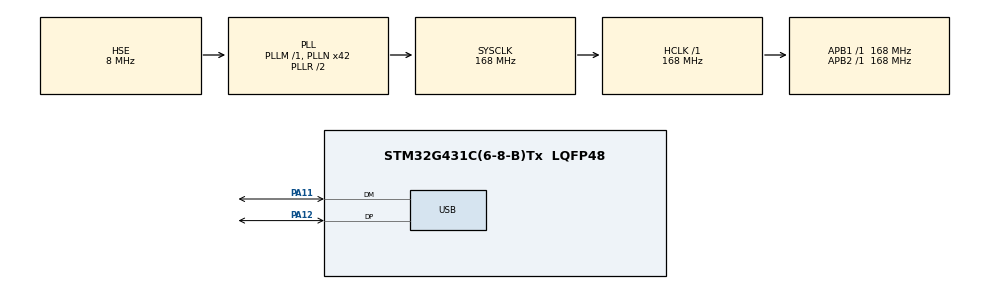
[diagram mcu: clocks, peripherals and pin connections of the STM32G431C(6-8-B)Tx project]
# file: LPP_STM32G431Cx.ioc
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Mcu.Family=STM32G4
Mcu.Name=STM32G431C(6-8-B)Tx
Mcu.Package=LQFP48
NVIC.PriorityGroup=NVIC_PRIORITYGROUP_4
NVIC.USB_LP_IRQn=true\:0\:0\:false\:false\:true\:false\:true\:true
PA11.Mode=Device
PA11.Signal=USB_DM
PA12.Mode=Device
PA12.Signal=USB_DP
PA13.Mode=Serial_Wire
PA13.Signal=SYS_JTMS-SWDIO
PA14.Mode=Serial_Wire
PA14.Signal=SYS_JTCK-SWCLK
PF0-OSC_IN.Mode=HSE-External-Oscillator
PF0-OSC_IN.Signal=RCC_OSC_IN
PF1-OSC_OUT.Mode=HSE-External-Oscillator
PF1-OSC_OUT.Signal=RCC_OSC_OUT
ProjectManager.HeapSize=0x200
ProjectManager.StackSize=0x400
ProjectManager.TargetToolchain=MDK-ARM V5.32
RCC.ADC12Freq_Value=168000000
RCC.AHBFreq_Value=168000000
RCC.APB1Freq_Value=168000000
RCC.APB1TimFreq_Value=168000000
RCC.APB2Freq_Value=168000000
RCC.APB2TimFreq_Value=168000000
RCC.CK48CLockSelection=RCC_USBCLKSOURCE_HSI48
RCC.CortexFreq_Value=168000000
RCC.EXTERNAL_CLOCK_VALUE=12288000
RCC.HCLKFreq_Value=168000000
RCC.HSE_VALUE=8000000
RCC.HSI48_VALUE=48000000
RCC.HSI_VALUE=16000000
RCC.PLLN=42
RCC.PLLSourceVirtual=RCC_PLLSOURCE_HSE
RCC.SYSCLKFreq_VALUE=168000000
RCC.SYSCLKSource=RCC_SYSCLKSOURCE_PLLCLK
RCC.USBFreq_Value=48000000
RCC.VCOOutputFreq_Value=336000000
USB_DEVICE.CLASS_NAME_FS=CUSTOM_HID
USB_DEVICE.CUSTOM_HID_FS_BINTERVAL=1
USB_DEVICE.USBD_CUSTOM_HID_REPORT_DESC_SIZE=34
USB_DEVICE.VID=1122
USB_DEVICE.VirtualMode=CustomHid
USB_DEVICE.VirtualModeFS=Custom_Hid_FS
VP_SYS_VS_DBSignals.Mode=DisableDeadBatterySignals
VP_USB_DEVICE_VS_USB_DEVICE_CUSTOM_HID_FS.Mode=CUSTOM_HID_FS
board=custom

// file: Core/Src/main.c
/* USER CODE BEGIN Header */
/**
  ******************************************************************************
  * @file           : main.c
  * @brief          : Main program body
  ******************************************************************************
  * @attention
  *
  * Copyright (c) 2025 STMicroelectronics.
  * All rights reserved.
  *
  * This software is licensed under terms that can be found in the LICENSE file
  * in the root directory of this software component.
  * If no LICENSE file comes with this software, it is provided AS-IS.
  *
  ******************************************************************************
  */
/* USER CODE END Header */
#include "main.h"
#include "usb_device.h"

/* USER CODE BEGIN Includes */
#include "counter.h"
#include "lib_boot.h"

/* USER CODE END Includes */

void SystemClock_Config(void);
static void MX_GPIO_Init(void);

/* USER CODE BEGIN 0 */
///////////////////////////////////////////////////////////////////////////////
// AECEEC79244F9766884016F20C4F36FA
const uint32_t APP_RESETI __attribute__((section(".ARM.__at_0x0800BFE8"))) = 0xFFFFFFFFU;
const uint32_t APP_KEY0 __attribute__((section(".ARM.__at_0x0800BFEC"))) = 0x43100000U;
const uint32_t APP_KEY1 __attribute__((section(".ARM.__at_0x0800BFF0"))) = 0x9ABCDEF0U;
const uint32_t APP_KEY2 __attribute__((section(".ARM.__at_0x0800BFF4"))) = 0x0F1E2D3CU;
const uint32_t APP_KEY3 __attribute__((section(".ARM.__at_0x0800BFF8"))) = 0x4B5A6978U;
const uint32_t APP_VER_F __attribute__((section(".ARM.__at_0x0800BFFC"))) = APP_VERSION;  // С counter.h переменная APP_VERSION

/* USER CODE END 0 */

int main(void)
{

  /* MCU Configuration--------------------------------------------------------*/

  /* Reset of all peripherals, Initializes the Flash interface and the Systick. */
  HAL_Init();

  /* Configure the system clock */
  SystemClock_Config();

  /* Initialize all configured peripherals */
  MX_GPIO_Init();
  MX_USB_Device_Init();
  /* USER CODE BEGIN 2 */

//USB->BCDR &= ~USB_BCDR_DPPU; // Выключаем D+ pull-up
//USB->BCDR |= USB_BCDR_DPPU; // Включаем D+ pull-up
USB_DevDisconnect(USB); // Выключаем D+ pull-up
USB_DevConnect(USB); // Включаем D+ pull-up

  /* USER CODE END 2 */

  /* Infinite loop */
  while (1)
  {

  }
}

void SystemClock_Config(void)
{
  RCC_OscInitTypeDef RCC_OscInitStruct = {0};
  RCC_ClkInitTypeDef RCC_ClkInitStruct = {0};

  /** Configure the main internal regulator output voltage
  */
  HAL_PWREx_ControlVoltageScaling(PWR_REGULATOR_VOLTAGE_SCALE1_BOOST);

  /** Initializes the RCC Oscillators according to the specified parameters
  * in the RCC_OscInitTypeDef structure.
  */
  RCC_OscInitStruct.OscillatorType = RCC_OSCILLATORTYPE_HSI48|RCC_OSCILLATORTYPE_HSE;
  RCC_OscInitStruct.HSEState = RCC_HSE_ON;
  RCC_OscInitStruct.HSI48State = RCC_HSI48_ON;
  RCC_OscInitStruct.PLL.PLLState = RCC_PLL_ON;
  RCC_OscInitStruct.PLL.PLLSource = RCC_PLLSOURCE_HSE;
  RCC_OscInitStruct.PLL.PLLM = RCC_PLLM_DIV1;
  RCC_OscInitStruct.PLL.PLLN = 42;
  RCC_OscInitStruct.PLL.PLLP = RCC_PLLP_DIV2;
  RCC_OscInitStruct.PLL.PLLQ = RCC_PLLQ_DIV2;
  RCC_OscInitStruct.PLL.PLLR = RCC_PLLR_DIV2;
  if (HAL_RCC_OscConfig(&RCC_OscInitStruct) != HAL_OK)
  {
    Error_Handler();
  }

  /** Initializes the CPU, AHB and APB buses clocks
  */
  RCC_ClkInitStruct.ClockType = RCC_CLOCKTYPE_HCLK|RCC_CLOCKTYPE_SYSCLK
                              |RCC_CLOCKTYPE_PCLK1|RCC_CLOCKTYPE_PCLK2;
  RCC_ClkInitStruct.SYSCLKSource = RCC_SYSCLKSOURCE_PLLCLK;
  RCC_ClkInitStruct.AHBCLKDivider = RCC_SYSCLK_DIV1;
  RCC_ClkInitStruct.APB1CLKDivider = RCC_HCLK_DIV1;
  RCC_ClkInitStruct.APB2CLKDivider = RCC_HCLK_DIV1;

  if (HAL_RCC_ClockConfig(&RCC_ClkInitStruct, FLASH_LATENCY_4) != HAL_OK)
  {
    Error_Handler();
  }
}

static void MX_GPIO_Init(void)
{

  /* GPIO Ports Clock Enable */
  __HAL_RCC_GPIOF_CLK_ENABLE();
  __HAL_RCC_GPIOA_CLK_ENABLE();

}

void Error_Handler(void)
{
  __disable_irq();
  while (1)
  {
  }
}
